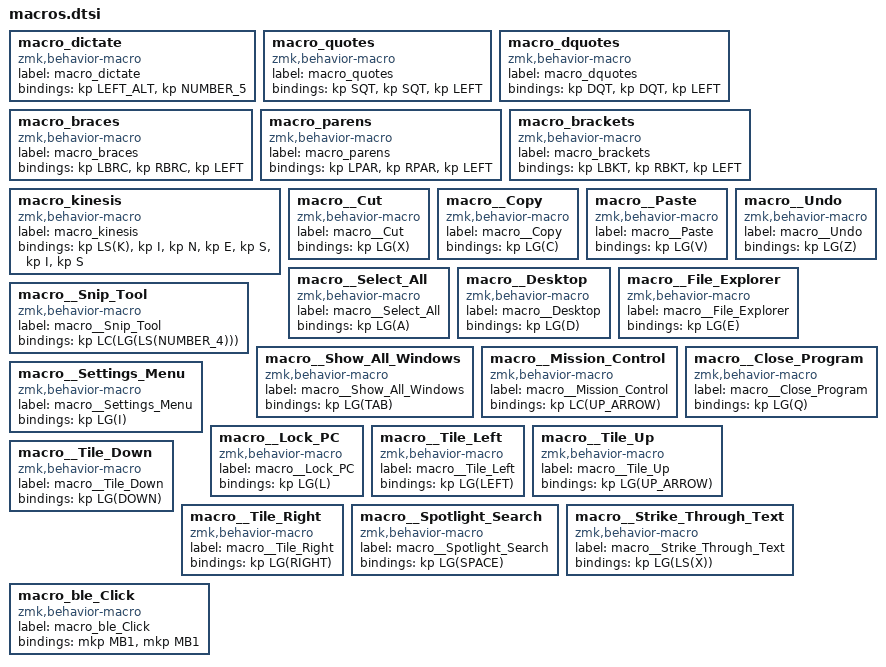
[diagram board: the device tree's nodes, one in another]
macro_dictate: macro_dictate{
compatible = "zmk,behavior-macro";
label = "macro_dictate";
#binding-cells = <0>;
bindings = <&kp LEFT_ALT>, <&kp NUMBER_5>;
};
macro_quotes: macro_quotes{
compatible = "zmk,behavior-macro";
label = "macro_quotes";
#binding-cells = <0>;
bindings = <&kp SQT>, <&kp SQT>, <&kp LEFT>;
};
macro_dquotes: macro_dquotes{
compatible = "zmk,behavior-macro";
label = "macro_dquotes";
#binding-cells = <0>;
bindings = <&kp DQT>, <&kp DQT>, <&kp LEFT>;
};
macro_braces: macro_braces{
compatible = "zmk,behavior-macro";
label = "macro_braces";
#binding-cells = <0>;
bindings = <&kp LBRC>, <&kp RBRC>, <&kp LEFT>;
};
macro_parens: macro_parens{
compatible = "zmk,behavior-macro";
label = "macro_parens";
#binding-cells = <0>;
bindings = <&kp LPAR>, <&kp RPAR>, <&kp LEFT>;
};
macro_brackets: macro_brackets{
compatible = "zmk,behavior-macro";
label = "macro_brackets";
#binding-cells = <0>;
bindings = <&kp LBKT>, <&kp RBKT>, <&kp LEFT>;
};
macro_kinesis: macro_kinesis{
compatible = "zmk,behavior-macro";
label = "macro_kinesis";
#binding-cells = <0>;
bindings = <&kp LS(K)>, <&kp I>, <&kp N>, <&kp E>, <&kp S>, <&kp I>, <&kp S>;
};
macro__Cut: macro__Cut{
compatible = "zmk,behavior-macro";
label = "macro__Cut";
#binding-cells = <0>;
bindings = <&kp LC(X)>;
};
macro__Copy: macro__Copy{
compatible = "zmk,behavior-macro";
label = "macro__Copy";
#binding-cells = <0>;
bindings = <&kp LC(C)>;
};
macro__Paste: macro__Paste{
compatible = "zmk,behavior-macro";
label = "macro__Paste";
#binding-cells = <0>;
bindings = <&kp LC(V)>;
};
macro__Select_All: macro__Select_All{
compatible = "zmk,behavior-macro";
label = "macro__Select_All";
#binding-cells = <0>;
bindings = <&kp LC(A)>;
};
macro__Undo: macro__Undo{
compatible = "zmk,behavior-macro";
label = "macro__Undo";
#binding-cells = <0>;
bindings = <&kp LC(Z)>;
};
macro__Desktop: macro__Desktop{
compatible = "zmk,behavior-macro";
label = "macro__Desktop";
#binding-cells = <0>;
bindings = <&kp LG(D)>;
};
macro__File_Explorer: macro__File_Explorer{
compatible = "zmk,behavior-macro";
label = "macro__File_Explorer";
#binding-cells = <0>;
bindings = <&kp LG(E)>;
};
macro__Snip_Tool: macro__Snip_Tool{
compatible = "zmk,behavior-macro";
label = "macro__Snip_Tool";
#binding-cells = <0>;
bindings = <&kp LS(LG(S))>;
};
macro__Show_All_Windows: macro__Show_All_Windows{
compatible = "zmk,behavior-macro";
label = "macro__Show_All_Windows";
#binding-cells = <0>;
bindings = <&kp LG(TAB)>;
};
macro__Cut: macro__Cut{
compatible = "zmk,behavior-macro";
label = "macro__Cut";
#binding-cells = <0>;
bindings = <&kp LG(X)>;
};
macro__Copy: macro__Copy{
compatible = "zmk,behavior-macro";
label = "macro__Copy";
#binding-cells = <0>;
bindings = <&kp LG(C)>;
};
macro__Paste: macro__Paste{
compatible = "zmk,behavior-macro";
label = "macro__Paste";
#binding-cells = <0>;
bindings = <&kp LG(V)>;
};
macro__Undo: macro__Undo{
compatible = "zmk,behavior-macro";
label = "macro__Undo";
#binding-cells = <0>;
bindings = <&kp LG(Z)>;
};
macro__Select_All: macro__Select_All{
compatible = "zmk,behavior-macro";
label = "macro__Select_All";
#binding-cells = <0>;
bindings = <&kp LG(A)>;
};
macro__Mission_Control: macro__Mission_Control{
compatible = "zmk,behavior-macro";
label = "macro__Mission_Control";
#binding-cells = <0>;
bindings = <&kp LC(UP_ARROW)>;
};
macro__Snip_Tool: macro__Snip_Tool{
compatible = "zmk,behavior-macro";
label = "macro__Snip_Tool";
#binding-cells = <0>;
bindings = <&kp LC(LG(LS(NUMBER_4)))>;
};
macro__Close_Program: macro__Close_Program{
compatible = "zmk,behavior-macro";
label = "macro__Close_Program";
#binding-cells = <0>;
bindings = <&kp LA(F4)>;
};
macro__Settings_Menu: macro__Settings_Menu{
compatible = "zmk,behavior-macro";
label = "macro__Settings_Menu";
#binding-cells = <0>;
bindings = <&kp LG(I)>;
};
macro__Lock_PC: macro__Lock_PC{
compatible = "zmk,behavior-macro";
label = "macro__Lock_PC";
#binding-cells = <0>;
bindings = <&kp LG(L)>;
};
macro__Tile_Left: macro__Tile_Left{
compatible = "zmk,behavior-macro";
label = "macro__Tile_Left";
#binding-cells = <0>;
bindings = <&kp LG(LEFT)>;
};
macro__Tile_Up: macro__Tile_Up{
compatible = "zmk,behavior-macro";
label = "macro__Tile_Up";
#binding-cells = <0>;
bindings = <&kp LG(UP_ARROW)>;
};
macro__Tile_Down: macro__Tile_Down{
compatible = "zmk,behavior-macro";
label = "macro__Tile_Down";
#binding-cells = <0>;
bindings = <&kp LG(DOWN)>;
};
macro__Tile_Right: macro__Tile_Right{
compatible = "zmk,behavior-macro";
label = "macro__Tile_Right";
#binding-cells = <0>;
bindings = <&kp LG(RIGHT)>;
};
macro__Spotlight_Search: macro__Spotlight_Search{
compatible = "zmk,behavior-macro";
label = "macro__Spotlight_Search";
#binding-cells = <0>;
bindings = <&kp LG(SPACE)>;
};
macro__Close_Program: macro__Close_Program{
compatible = "zmk,behavior-macro";
label = "macro__Close_Program";
#binding-cells = <0>;
bindings = <&kp LG(Q)>;
};
macro__Strike_Through_Text: macro__Strike_Through_Text{
compatible = "zmk,behavior-macro";
label = "macro__Strike_Through_Text";
#binding-cells = <0>;
bindings = <&kp LG(LS(X))>;
};
macro_ble_Click: macro_ble_Click{
compatible = "zmk,behavior-macro";
label = "macro_ble_Click";
#binding-cells = <0>;
bindings = <&mkp MB1 &mkp MB1>;
};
